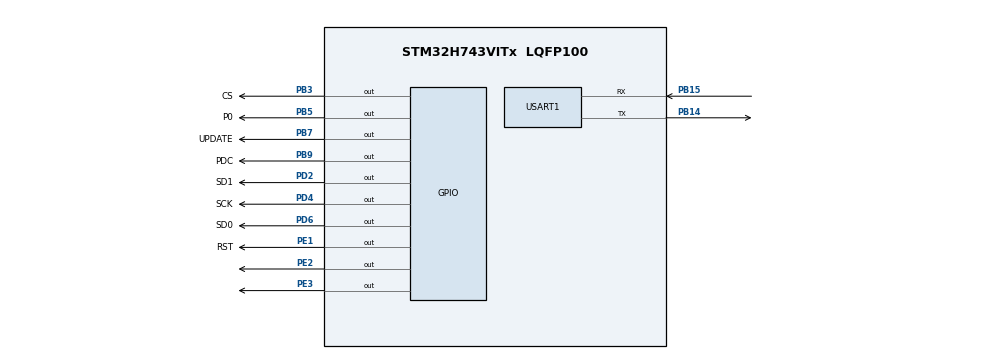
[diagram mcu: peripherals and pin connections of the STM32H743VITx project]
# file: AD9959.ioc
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CORTEX_M7.AccessPermission-Cortex_Memory_Protection_Unit_Region0_Settings=MPU_REGION_FULL_ACCESS
CORTEX_M7.AccessPermission-Cortex_Memory_Protection_Unit_Region1_Settings=MPU_REGION_FULL_ACCESS
CORTEX_M7.AccessPermission-Cortex_Memory_Protection_Unit_Region2_Settings=MPU_REGION_FULL_ACCESS
CORTEX_M7.AccessPermission-Cortex_Memory_Protection_Unit_Region3_Settings=MPU_REGION_FULL_ACCESS
CORTEX_M7.AccessPermission-Cortex_Memory_Protection_Unit_Region4_Settings=MPU_REGION_FULL_ACCESS
CORTEX_M7.AccessPermission_S-Cortex_Memory_Protection_Unit_Region1_Settings_S=MPU_REGION_FULL_ACCESS
CORTEX_M7.AccessPermission_S-Cortex_Memory_Protection_Unit_Region2_Settings_S=MPU_REGION_FULL_ACCESS
CORTEX_M7.AccessPermission_Spec=MPU_REGION_FULL_ACCESS
CORTEX_M7.BaseAddress-Cortex_Memory_Protection_Unit_Region0_Settings=0x24000000
CORTEX_M7.BaseAddress-Cortex_Memory_Protection_Unit_Region1_Settings=0x30000000
CORTEX_M7.BaseAddress-Cortex_Memory_Protection_Unit_Region2_Settings=0x30020000
CORTEX_M7.BaseAddress-Cortex_Memory_Protection_Unit_Region3_Settings=0x30040000
CORTEX_M7.BaseAddress-Cortex_Memory_Protection_Unit_Region4_Settings=0x38000000
CORTEX_M7.BaseAddress_S-Cortex_Memory_Protection_Unit_Region1_Settings_S=0x30000000
CORTEX_M7.BaseAddress_S-Cortex_Memory_Protection_Unit_Region2_Settings_S=0x30020000
CORTEX_M7.BaseAddress_Spec=0x24000000
CORTEX_M7.CPU_DCache=Enabled
CORTEX_M7.CPU_ICache=Enabled
CORTEX_M7.DisableExec_S-Cortex_Memory_Protection_Unit_Region1_Settings_S=MPU_INSTRUCTION_ACCESS_ENABLE
CORTEX_M7.DisableExec_S-Cortex_Memory_Protection_Unit_Region2_Settings_S=MPU_INSTRUCTION_ACCESS_ENABLE
CORTEX_M7.DisableExec_Spec=MPU_INSTRUCTION_ACCESS_ENABLE
CORTEX_M7.Enable-Cortex_Memory_Protection_Unit_Region0_Settings=MPU_REGION_ENABLE
CORTEX_M7.Enable-Cortex_Memory_Protection_Unit_Region1_Settings=MPU_REGION_ENABLE
CORTEX_M7.Enable-Cortex_Memory_Protection_Unit_Region2_Settings=MPU_REGION_ENABLE
CORTEX_M7.Enable-Cortex_Memory_Protection_Unit_Region3_Settings=MPU_REGION_ENABLE
CORTEX_M7.Enable-Cortex_Memory_Protection_Unit_Region4_Settings=MPU_REGION_ENABLE
CORTEX_M7.Enable_S-Cortex_Memory_Protection_Unit_Region1_Settings_S=MPU_REGION_ENABLE
CORTEX_M7.Enable_S-Cortex_Memory_Protection_Unit_Region2_Settings_S=MPU_REGION_ENABLE
CORTEX_M7.IsBufferable-Cortex_Memory_Protection_Unit_Region0_Settings=MPU_ACCESS_BUFFERABLE
CORTEX_M7.IsBufferable_S-Cortex_Memory_Protection_Unit_Region1_Settings_S=MPU_ACCESS_NOT_BUFFERABLE
CORTEX_M7.IsBufferable_Spec=MPU_ACCESS_BUFFERABLE
CORTEX_M7.IsCacheable-Cortex_Memory_Protection_Unit_Region0_Settings=MPU_ACCESS_CACHEABLE
CORTEX_M7.IsCacheable_S-Cortex_Memory_Protection_Unit_Region1_Settings_S=MPU_ACCESS_NOT_CACHEABLE
CORTEX_M7.IsCacheable_Spec=MPU_ACCESS_CACHEABLE
CORTEX_M7.IsShareable_Spec=MPU_ACCESS_NOT_SHAREABLE
CORTEX_M7.MPU_Control=MPU_PRIVILEGED_DEFAULT
CORTEX_M7.Size-Cortex_Memory_Protection_Unit_Region0_Settings=MPU_REGION_SIZE_512KB
CORTEX_M7.Size-Cortex_Memory_Protection_Unit_Region1_Settings=MPU_REGION_SIZE_128KB
CORTEX_M7.Size-Cortex_Memory_Protection_Unit_Region2_Settings=MPU_REGION_SIZE_128KB
CORTEX_M7.Size-Cortex_Memory_Protection_Unit_Region3_Settings=MPU_REGION_SIZE_32KB
CORTEX_M7.Size-Cortex_Memory_Protection_Unit_Region4_Settings=MPU_REGION_SIZE_64KB
CORTEX_M7.Size_S-Cortex_Memory_Protection_Unit_Region1_Settings_S=MPU_REGION_SIZE_128KB
CORTEX_M7.Size_S-Cortex_Memory_Protection_Unit_Region2_Settings_S=MPU_REGION_SIZE_128KB
CORTEX_M7.Size_Spec=MPU_REGION_SIZE_512KB
CORTEX_M7.SubRegionDisable_Spec=0x0
CORTEX_M7.TypeExtField-Cortex_Memory_Protection_Unit_Region0_Settings=MPU_TEX_LEVEL1
CORTEX_M7.TypeExtField-Cortex_Memory_Protection_Unit_Region1_Settings=MPU_TEX_LEVEL1
CORTEX_M7.TypeExtField-Cortex_Memory_Protection_Unit_Region2_Settings=MPU_TEX_LEVEL1
CORTEX_M7.TypeExtField-Cortex_Memory_Protection_Unit_Region3_Settings=MPU_TEX_LEVEL1
CORTEX_M7.TypeExtField-Cortex_Memory_Protection_Unit_Region4_Settings=MPU_TEX_LEVEL1
CORTEX_M7.TypeExtField_S-Cortex_Memory_Protection_Unit_Region1_Settings_S=MPU_TEX_LEVEL1
CORTEX_M7.TypeExtField_S-Cortex_Memory_Protection_Unit_Region2_Settings_S=MPU_TEX_LEVEL1
CORTEX_M7.TypeExtField_Spec=MPU_TEX_LEVEL1
Mcu.Family=STM32H7
Mcu.Name=STM32H743VITx
Mcu.Package=LQFP100
NVIC.PriorityGroup=NVIC_PRIORITYGROUP_4
NVIC.TIM17_IRQn=true\:0\:0\:false\:false\:true\:true\:true\:true
PA13\ (JTMS/SWDIO).Mode=Serial_Wire
PA13\ (JTMS/SWDIO).Signal=DEBUG_JTMS-SWDIO
PA14\ (JTCK/SWCLK).Mode=Serial_Wire
PA14\ (JTCK/SWCLK).Signal=DEBUG_JTCK-SWCLK
PB14.Mode=Asynchronous
PB14.Signal=USART1_TX
PB15.Mode=Asynchronous
PB15.Signal=USART1_RX
PB3\ (JTDO/TRACESWO).GPIO_Label=CS
PB3\ (JTDO/TRACESWO).GPIO_PuPd=GPIO_PULLDOWN
PB3\ (JTDO/TRACESWO).GPIO_Speed=GPIO_SPEED_FREQ_VERY_HIGH
PB3\ (JTDO/TRACESWO).Signal=GPIO_Output
PB5.GPIO_Label=P0
PB5.GPIO_PuPd=GPIO_PULLDOWN
PB5.GPIO_Speed=GPIO_SPEED_FREQ_VERY_HIGH
PB5.Signal=GPIO_Output
PB7.GPIO_FM7=__NULL
PB7.GPIO_Label=UPDATE
PB7.GPIO_PuPd=GPIO_PULLDOWN
PB7.GPIO_Speed=GPIO_SPEED_FREQ_VERY_HIGH
PB7.Signal=GPIO_Output
PB9.GPIO_FM9=__NULL
PB9.GPIO_Label=PDC
PB9.GPIO_PuPd=GPIO_PULLDOWN
PB9.GPIO_Speed=GPIO_SPEED_FREQ_VERY_HIGH
PB9.Signal=GPIO_Output
PD2.GPIO_Label=SD1
PD2.GPIO_PuPd=GPIO_PULLDOWN
PD2.GPIO_Speed=GPIO_SPEED_FREQ_VERY_HIGH
PD2.Signal=GPIO_Output
PD4.GPIO_Label=SCK
PD4.GPIO_PuPd=GPIO_PULLDOWN
PD4.GPIO_Speed=GPIO_SPEED_FREQ_VERY_HIGH
PD4.Signal=GPIO_Output
PD6.GPIO_Label=SD0
PD6.GPIO_Speed=GPIO_SPEED_FREQ_VERY_HIGH
PD6.Signal=GPIO_Output
PE1.GPIO_Label=RST
PE1.GPIO_Speed=GPIO_SPEED_FREQ_VERY_HIGH
PE1.Signal=GPIO_Output
PE2.GPIO_PuPd=GPIO_PULLUP
PE2.GPIO_Speed=GPIO_SPEED_FREQ_VERY_HIGH
PE2.PinState=GPIO_PIN_SET
PE2.Signal=GPIO_Output
PE3.GPIO_PuPd=GPIO_PULLUP
PE3.GPIO_Speed=GPIO_SPEED_FREQ_VERY_HIGH
PE3.PinState=GPIO_PIN_SET
PE3.Signal=GPIO_Output
PH0-OSC_IN\ (PH0).Mode=HSE-External-Oscillator
PH0-OSC_IN\ (PH0).Signal=RCC_OSC_IN
PH1-OSC_OUT\ (PH1).Mode=HSE-External-Oscillator
PH1-OSC_OUT\ (PH1).Signal=RCC_OSC_OUT
ProjectManager.HeapSize=0x200
ProjectManager.StackSize=0x400
ProjectManager.TargetToolchain=MDK-ARM V5.32
RCC.ADCFreq_Value=50390625
RCC.APB1Freq_Value=100000000
RCC.APB2Freq_Value=100000000
RCC.APB3Freq_Value=100000000
RCC.APB4Freq_Value=100000000
RCC.CortexFreq_Value=400000000
RCC.D1PPRE=RCC_APB3_DIV2
RCC.D2PPRE1=RCC_APB1_DIV2
RCC.D2PPRE2=RCC_APB2_DIV2
RCC.D3PPRE=RCC_APB4_DIV2
RCC.DIVM1=5
RCC.DIVN1=160
RCC.HCLKFreq_Value=200000000
RCC.HPRE=RCC_HCLK_DIV2
RCC.HSE_Timout=5000
RCC.PLLSourceVirtual=RCC_PLLSOURCE_HSE
RCC.SYSCLKFreq_VALUE=400000000
RCC.SYSCLKSource=RCC_SYSCLKSOURCE_PLLCLK
RCC.USBFreq_Value=400000000
TIM17.AutoReloadPreload=TIM_AUTORELOAD_PRELOAD_ENABLE
TIM17.Period=999
TIM17.Prescaler=2499
TIM7.Prescaler=199
USART1.VirtualMode-Asynchronous=VM_ASYNC
VP_TIM17_VS_ClockSourceINT.Mode=Enable_Timer
VP_TIM7_VS_ClockSourceINT.Mode=Enable_Timer
board=custom

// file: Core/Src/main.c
/* USER CODE BEGIN Header */
/**
  ******************************************************************************
  * @file           : main.c
  * @brief          : Main program body
  ******************************************************************************
  * @attention
  *
  * Copyright (c) 2022 STMicroelectronics.
  * All rights reserved.
  *
  * This software is licensed under terms that can be found in the LICENSE file
  * in the root directory of this software component.
  * If no LICENSE file comes with this software, it is provided AS-IS.
  *
  ******************************************************************************
  */
/* USER CODE END Header */
#include "main.h"
#include "tim.h"
#include "usart.h"
#include "gpio.h"

/* USER CODE BEGIN Includes */
uint32_t sendata 				= 0;
uint32_t sendtwo[14] 		= {0};
uint32_t AJcode[4] 			= {0};
uint32_t AJcode_flag[4] = {0};

/* USER CODE END Includes */

void SystemClock_Config(void);
static void MPU_Config(void);

int main(void)
{

  /* MPU Configuration--------------------------------------------------------*/
  MPU_Config();

  /* Enable I-Cache---------------------------------------------------------*/
  SCB_EnableICache();

  /* Enable D-Cache---------------------------------------------------------*/
  SCB_EnableDCache();

  /* MCU Configuration--------------------------------------------------------*/

  /* Reset of all peripherals, Initializes the Flash interface and the Systick. */
  HAL_Init();

  /* Configure the system clock */
  SystemClock_Config();

  /* Initialize all configured peripherals */
  MX_GPIO_Init();
  MX_TIM7_Init();
  MX_USART1_UART_Init();
  MX_TIM17_Init();
  /* USER CODE BEGIN 2 */
	Init_AD9959();
  uint32_t freq = 10000000;
	Write_frequence(2,12000);
	Write_frequence(3,25000000);
  HAL_TIM_Base_Start_IT(&htim17);

  while(1)
  {

  /* USER CODE END 2 */

  /* Infinite loop */
  /* USER CODE BEGIN WHILE */
//		Write_frequence(2,0);
//		Delay_Us(6250);
//		Write_frequence(2,12000);
//		Delay_Us(6250);

//  for(uint32_t i=0;i<10000;i++)
//  {
//		freq += 10000;
//		Write_frequence(0,freq);
//		Delay_Us(3);
//	}
//
//
    /* USER CODE END WHILE */

    /* USER CODE BEGIN 3 */
//
  }
  /* USER CODE END 3 */
}

void SystemClock_Config(void)
{
  RCC_OscInitTypeDef RCC_OscInitStruct = {0};
  RCC_ClkInitTypeDef RCC_ClkInitStruct = {0};

  /** Supply configuration update enable
  */
  HAL_PWREx_ConfigSupply(PWR_LDO_SUPPLY);

  /** Configure the main internal regulator output voltage
  */
  __HAL_PWR_VOLTAGESCALING_CONFIG(PWR_REGULATOR_VOLTAGE_SCALE1);

  while(!__HAL_PWR_GET_FLAG(PWR_FLAG_VOSRDY)) {}

  /** Initializes the RCC Oscillators according to the specified parameters
  * in the RCC_OscInitTypeDef structure.
  */
  RCC_OscInitStruct.OscillatorType = RCC_OSCILLATORTYPE_HSE;
  RCC_OscInitStruct.HSEState = RCC_HSE_ON;
  RCC_OscInitStruct.PLL.PLLState = RCC_PLL_ON;
  RCC_OscInitStruct.PLL.PLLSource = RCC_PLLSOURCE_HSE;
  RCC_OscInitStruct.PLL.PLLM = 5;
  RCC_OscInitStruct.PLL.PLLN = 160;
  RCC_OscInitStruct.PLL.PLLP = 2;
  RCC_OscInitStruct.PLL.PLLQ = 2;
  RCC_OscInitStruct.PLL.PLLR = 2;
  RCC_OscInitStruct.PLL.PLLRGE = RCC_PLL1VCIRANGE_2;
  RCC_OscInitStruct.PLL.PLLVCOSEL = RCC_PLL1VCOWIDE;
  RCC_OscInitStruct.PLL.PLLFRACN = 0;
  if (HAL_RCC_OscConfig(&RCC_OscInitStruct) != HAL_OK)
  {
    Error_Handler();
  }

  /** Initializes the CPU, AHB and APB buses clocks
  */
  RCC_ClkInitStruct.ClockType = RCC_CLOCKTYPE_HCLK|RCC_CLOCKTYPE_SYSCLK
                              |RCC_CLOCKTYPE_PCLK1|RCC_CLOCKTYPE_PCLK2
                              |RCC_CLOCKTYPE_D3PCLK1|RCC_CLOCKTYPE_D1PCLK1;
  RCC_ClkInitStruct.SYSCLKSource = RCC_SYSCLKSOURCE_PLLCLK;
  RCC_ClkInitStruct.SYSCLKDivider = RCC_SYSCLK_DIV1;
  RCC_ClkInitStruct.AHBCLKDivider = RCC_HCLK_DIV2;
  RCC_ClkInitStruct.APB3CLKDivider = RCC_APB3_DIV2;
  RCC_ClkInitStruct.APB1CLKDivider = RCC_APB1_DIV2;
  RCC_ClkInitStruct.APB2CLKDivider = RCC_APB2_DIV2;
  RCC_ClkInitStruct.APB4CLKDivider = RCC_APB4_DIV2;

  if (HAL_RCC_ClockConfig(&RCC_ClkInitStruct, FLASH_LATENCY_2) != HAL_OK)
  {
    Error_Handler();
  }
}

/* MPU Configuration */

void MPU_Config(void)
{
  MPU_Region_InitTypeDef MPU_InitStruct = {0};

  /* Disables the MPU */
  HAL_MPU_Disable();

  /** Initializes and configures the Region and the memory to be protected
  */
  MPU_InitStruct.Enable = MPU_REGION_ENABLE;
  MPU_InitStruct.Number = MPU_REGION_NUMBER0;
  MPU_InitStruct.BaseAddress = 0x24000000;
  MPU_InitStruct.Size = MPU_REGION_SIZE_512KB;
  MPU_InitStruct.SubRegionDisable = 0x0;
  MPU_InitStruct.TypeExtField = MPU_TEX_LEVEL1;
  MPU_InitStruct.AccessPermission = MPU_REGION_FULL_ACCESS;
  MPU_InitStruct.DisableExec = MPU_INSTRUCTION_ACCESS_ENABLE;
  MPU_InitStruct.IsShareable = MPU_ACCESS_NOT_SHAREABLE;
  MPU_InitStruct.IsCacheable = MPU_ACCESS_CACHEABLE;
  MPU_InitStruct.IsBufferable = MPU_ACCESS_BUFFERABLE;

  HAL_MPU_ConfigRegion(&MPU_InitStruct);

  /** Initializes and configures the Region and the memory to be protected
  */
  MPU_InitStruct.Number = MPU_REGION_NUMBER1;
  MPU_InitStruct.BaseAddress = 0x30000000;
  MPU_InitStruct.Size = MPU_REGION_SIZE_128KB;
  MPU_InitStruct.IsCacheable = MPU_ACCESS_NOT_CACHEABLE;
  MPU_InitStruct.IsBufferable = MPU_ACCESS_NOT_BUFFERABLE;

  HAL_MPU_ConfigRegion(&MPU_InitStruct);

  /** Initializes and configures the Region and the memory to be protected
  */
  MPU_InitStruct.Number = MPU_REGION_NUMBER2;
  MPU_InitStruct.BaseAddress = 0x30020000;

  HAL_MPU_ConfigRegion(&MPU_InitStruct);

  /** Initializes and configures the Region and the memory to be protected
  */
  MPU_InitStruct.Number = MPU_REGION_NUMBER3;
  MPU_InitStruct.BaseAddress = 0x30040000;
  MPU_InitStruct.Size = MPU_REGION_SIZE_32KB;

  HAL_MPU_ConfigRegion(&MPU_InitStruct);

  /** Initializes and configures the Region and the memory to be protected
  */
  MPU_InitStruct.Number = MPU_REGION_NUMBER4;
  MPU_InitStruct.BaseAddress = 0x38000000;
  MPU_InitStruct.Size = MPU_REGION_SIZE_64KB;

  HAL_MPU_ConfigRegion(&MPU_InitStruct);
  /* Enables the MPU */
  HAL_MPU_Enable(MPU_PRIVILEGED_DEFAULT);

}

void Error_Handler(void)
{
  __disable_irq();
  while (1)
  {
  }
}
